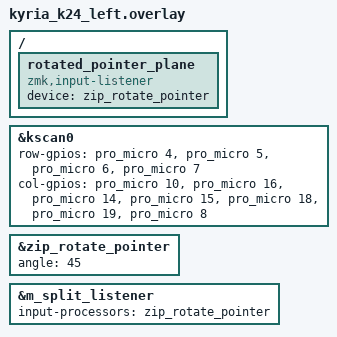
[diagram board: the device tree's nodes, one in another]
/*
 * Copyright (c) 2023 The ZMK Contributors
 *
 * SPDX-License-Identifier: MIT
 */

#include "kyria_k24.dtsi"
#include <input/processors/rotate_plane.dtsi>

&kscan0 {
    row-gpios
    = <&pro_micro 4 (GPIO_ACTIVE_HIGH | GPIO_PULL_DOWN)>
    , <&pro_micro 5 (GPIO_ACTIVE_HIGH | GPIO_PULL_DOWN)>
    , <&pro_micro 6 (GPIO_ACTIVE_HIGH | GPIO_PULL_DOWN)>
    , <&pro_micro 7 (GPIO_ACTIVE_HIGH | GPIO_PULL_DOWN)>
    ;
    col-gpios
    = <&pro_micro 10 GPIO_ACTIVE_HIGH>
    , <&pro_micro 16 GPIO_ACTIVE_HIGH>
    , <&pro_micro 14 GPIO_ACTIVE_HIGH>
    , <&pro_micro 15 GPIO_ACTIVE_HIGH>
    , <&pro_micro 18 GPIO_ACTIVE_HIGH>
    , <&pro_micro 19 GPIO_ACTIVE_HIGH>
    , <&pro_micro 8 GPIO_ACTIVE_HIGH>
    ;
};
/*
&pointer_accel { // this needs to be put BEFORE input-listener
    input-type = <INPUT_EV_REL>;
    codes = <INPUT_REL_X INPUT_REL_Y>;
    sensitivity = <800>;         // 0.8x base sensitivity
	min-factor = <800>;			  // 0.8x minimum for percision
    max-factor = <3000>;          // 3.0x maximum acceleration
    acceleration-exponent = <1>;  // Advanced exponential curve (1-5)
    y-boost = <1100>;             // 1.1x Y-axis boost for widescreen
    speed-threshold = <900>;      // Start acceleration at 900 counts/sec, just 1.5 inch/sec
    speed-max = <1800>;           // Max acceleration at 1800 counts/sec, just 3 inch/sec
    min-factor = <1000>;          // 1.0x minimum (no deceleration)
	sensor-dpi = <600>;
};
*/

&zip_rotate_pointer {
    angle = <45>;
};

&m_split_listener {
    status = "okay";
    input-processors = <&zip_rotate_pointer>;
    //input-processors = <&pointer_accel>;

};

/ {
    rotated_pointer_plane {
        compatible = "zmk,input-listener";
        device = <&zip_rotate_pointer>;
    };
};
